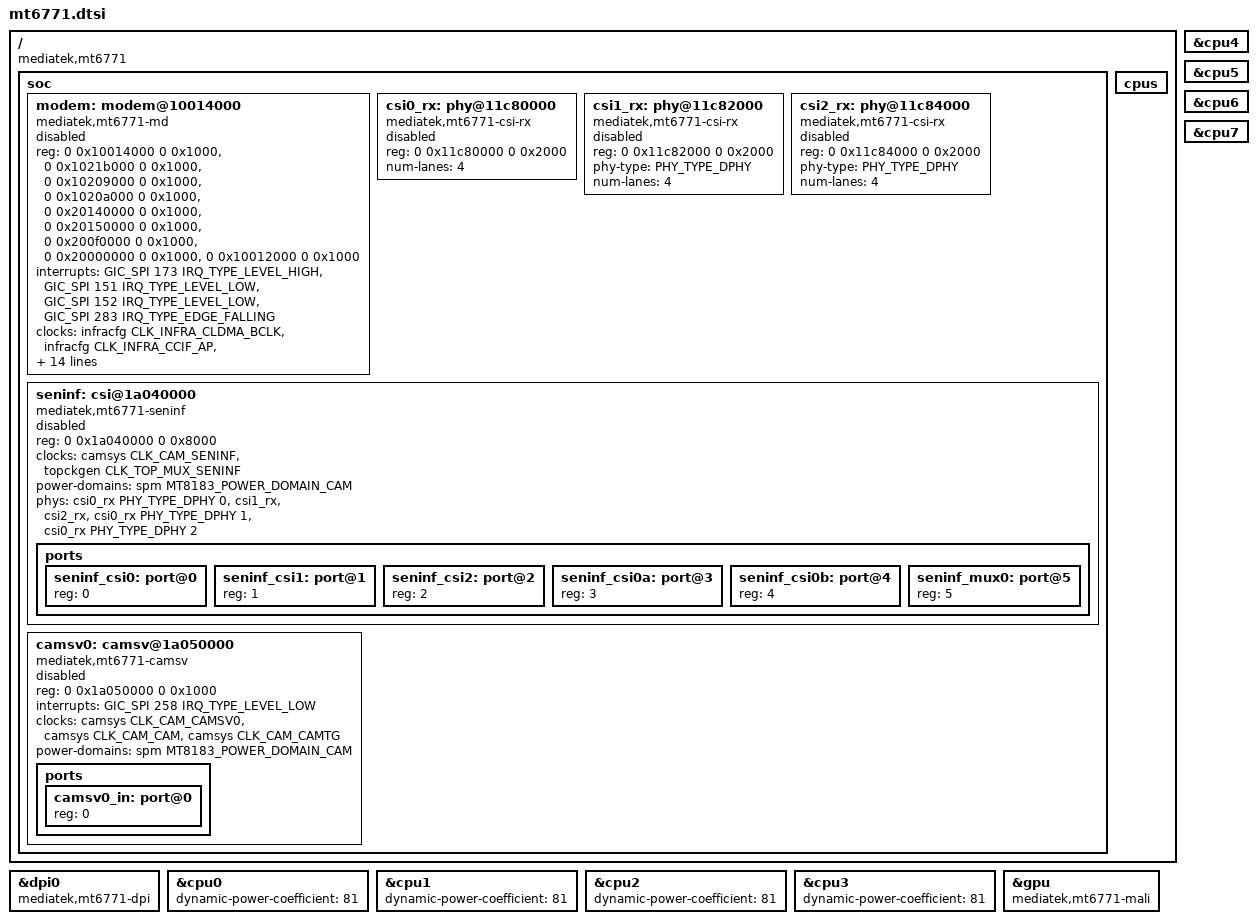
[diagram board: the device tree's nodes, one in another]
// SPDX-License-Identifier: (GPL-2.0 OR MIT)
/*
 * MediaTek MT6771 (Helio P60/P70).
 *
 * MT6771 is MT8183 silicon with a different product name and a different mix of blocks. Measured against
 * mainline's mt8183.dtsi, 85 of its 88 peripheral nodes sit at identical base addresses on MT6771; the
 * three that do not are svs (0x1100bc00), usb (0x11201000) and t-phy (0x11f40000). Everything needed to
 * reach a console — GIC at 0x0c000000, uart0 at 0x11002000, sys_timer, toprgu, topckgen, infracfg,
 * apmixedsys — matches exactly, and the vendor tree's own UART compatible is mediatek,mt6577-uart, the
 * same one mainline has matched on since 2012.
 *
 * So inherit rather than translate. An earlier version of this file described the SoC from scratch, ~400
 * lines with every node citing a line of the vendor dts (see git history, and notes 01-dtsi). That
 * translation was correct as far as it was checked — cpus, psci, timer and GIC all matched the vendor
 * exactly — but it obtains by hand what mainline already expresses in bindings that were reviewed, and
 * it differs from the only configuration known to have booted this device (Otto Pflüger's tree, which
 * does the same include).
 *
 * What is genuinely Cosmo-specific, and was read off the running device rather than from any tree, lives
 * in mt6771-planet-cosmo.dts: the memory size, the firmware-owned reservations, the framebuffer.
 */

#include <dt-bindings/phy/phy.h>

#include "mt8183.dtsi"

/ {
	compatible = "mediatek,mt6771";
};

/* same DPI block, but the vendor clocks it at 148.5 MHz for 1080p60, past the MT8183 limit */
&dpi0 {
	compatible = "mediatek,mt6771-dpi", "mediatek,mt8183-dpi";
};

/*
 * cpuidle stays off: the vendor enters idle through MCDI in the SSPM, and whether this firmware
 * honours the plain PSCI states mt8183.dtsi describes is not established. The mt8183 OPP tables
 * stay: they equal the vendor's V5_4 speed bin and are at or above the V5_T bin at every point.
 * A53 dynamic power: the vendor upower table gives 81.5 uW/MHz/V^2 at every OPP
 * (mtk_unified_power_data_mt6771.h upower_tbl_l_FY4); the A73 value 211 already matches.
 */
&cpu0 {
	/delete-property/ cpu-idle-states;
	dynamic-power-coefficient = <81>;
};

&cpu1 {
	/delete-property/ cpu-idle-states;
	dynamic-power-coefficient = <81>;
};

&cpu2 {
	/delete-property/ cpu-idle-states;
	dynamic-power-coefficient = <81>;
};

&cpu3 {
	/delete-property/ cpu-idle-states;
	dynamic-power-coefficient = <81>;
};

&cpu4 {
	/delete-property/ cpu-idle-states;
};

&cpu5 {
	/delete-property/ cpu-idle-states;
};

&cpu6 {
	/delete-property/ cpu-idle-states;
};

&cpu7 {
	/delete-property/ cpu-idle-states;
};

/*
 * The modem (MD1, generation 6293) and the two blocks the AP talks to it through: CLDMA, a
 * descriptor DMA for the network queues, and CCIF, a mailbox with a small SRAM that carries the
 * handshake and control path. MT8183 has no modem, so none of this is in mt8183.dtsi.
 * Addresses, interrupts and clocks are the vendor's mdcldma node (V:1281-1310), identical in the
 * live tree the bootloader hands the vendor kernel. The clock gates are the same bits in
 * mainline's MT8183 infracfg driver as in the vendor's MT6771 one, and the three resets are the
 * bits the vendor's md_cldma_hw_reset() and ccci_reset_ccif_hw() write by hand (infracfg 0x140
 * bit 6, 0x150 bits 2 and 8). No power-domains yet: mainline's MT8183 SPM has no MD1 domain.
 *
 * Disabled: the driver has only been built, never run against the device.
 */
/ {
	soc {
		modem: modem@10014000 {
			compatible = "mediatek,mt6771-md";
			reg = <0 0x10014000 0 0x1000>,
			      <0 0x1021b000 0 0x1000>,
			      <0 0x10209000 0 0x1000>,
			      <0 0x1020a000 0 0x1000>,
			      <0 0x20140000 0 0x1000>,
			      <0 0x20150000 0 0x1000>,
			      <0 0x200f0000 0 0x1000>,
			      <0 0x20000000 0 0x1000>,
			      <0 0x10012000 0 0x1000>;
			reg-names = "cldma-ao", "cldma-pd", "ap-ccif", "md-ccif",
				    "md-pll", "md-clksw", "md-rgu", "md-boot", "dvfsrc";
			interrupts = <GIC_SPI 173 IRQ_TYPE_LEVEL_HIGH>,
				     <GIC_SPI 151 IRQ_TYPE_LEVEL_LOW>,
				     <GIC_SPI 152 IRQ_TYPE_LEVEL_LOW>,
				     <GIC_SPI 283 IRQ_TYPE_EDGE_FALLING>;
			interrupt-names = "cldma", "ccif0", "ccif1", "wdt";
			clocks = <&infracfg CLK_INFRA_CLDMA_BCLK>,
				 <&infracfg CLK_INFRA_CCIF_AP>,
				 <&infracfg CLK_INFRA_CCIF_MD>,
				 <&infracfg CLK_INFRA_CCIF1_AP>,
				 <&infracfg CLK_INFRA_CCIF1_MD>,
				 <&infracfg CLK_INFRA_CCIF2_AP>,
				 <&infracfg CLK_INFRA_CCIF2_MD>,
				 <&infracfg CLK_INFRA_DVFSRC>;
			clock-names = "cldma", "ccif-ap", "ccif-md", "ccif1-ap",
				      "ccif1-md", "ccif2-ap", "ccif2-md", "dvfsrc";
			resets = <&infracfg MT8183_INFRACFG_AO_CLDMA_AO_SW_RST>,
				 <&infracfg MT8183_INFRACFG_AO_CLDMA_SW_RST>,
				 <&infracfg MT8183_INFRACFG_AO_AP_MD_CCIF_SW_RST>;
			reset-names = "cldma-ao", "cldma-pd", "ccif";
			mediatek,scpsys = <&scpsys>;
			mediatek,infracfg = <&infracfg>;
			mediatek,topckgen = <&topckgen>;
			mediatek,apmixedsys = <&apmixedsys>;
			status = "disabled";
		};
	};
};

/*
 * MIPI CSI-2 receiver: three analog D-PHY receivers (CSI0 can also be split into two 2 lane halves)
 * and the SENINF decoders behind them. Layout, clocks and the CAM power domain are those of
 * MT8183 (vendor mt6771.dts: analog 0x11c80000 in six 0x1000 blocks, SENINF 0x1a040000 in eight
 * pages, same camsys gate). The vendor left the SENINF interrupt (SPI 251) disabled and it is not
 * described here. Which port a sensor uses is board specific: the board hangs its sensors on the
 * ports. Disabled: the driver has only been built, never run against the device.
 *
 * CAMSV0 (0x1a050000, SPI 258) takes the stream of SENINF mux 0. The DMA has no known IOMMU port
 * yet, so the board gives it a memory region and the larbs to keep powered.
 */
/ {
	soc {
		csi0_rx: phy@11c80000 {
			compatible = "mediatek,mt6771-csi-rx", "mediatek,mt8183-csi-rx";
			reg = <0 0x11c80000 0 0x2000>;
			num-lanes = <4>;
			#phy-cells = <2>;
			status = "disabled";
		};

		csi1_rx: phy@11c82000 {
			compatible = "mediatek,mt6771-csi-rx", "mediatek,mt8183-csi-rx";
			reg = <0 0x11c82000 0 0x2000>;
			phy-type = <PHY_TYPE_DPHY>;
			num-lanes = <4>;
			#phy-cells = <0>;
			status = "disabled";
		};

		csi2_rx: phy@11c84000 {
			compatible = "mediatek,mt6771-csi-rx", "mediatek,mt8183-csi-rx";
			reg = <0 0x11c84000 0 0x2000>;
			phy-type = <PHY_TYPE_DPHY>;
			num-lanes = <4>;
			#phy-cells = <0>;
			status = "disabled";
		};

		seninf: csi@1a040000 {
			compatible = "mediatek,mt6771-seninf", "mediatek,mt8183-seninf";
			reg = <0 0x1a040000 0 0x8000>;
			clocks = <&camsys CLK_CAM_SENINF>,
				 <&topckgen CLK_TOP_MUX_SENINF>;
			clock-names = "seninf", "seninf_mux";
			power-domains = <&spm MT8183_POWER_DOMAIN_CAM>;
			phys = <&csi0_rx PHY_TYPE_DPHY 0>, <&csi1_rx>, <&csi2_rx>,
			       <&csi0_rx PHY_TYPE_DPHY 1>, <&csi0_rx PHY_TYPE_DPHY 2>;
			phy-names = "csi0", "csi1", "csi2", "csi0a", "csi0b";
			status = "disabled";

			ports {
				#address-cells = <1>;
				#size-cells = <0>;

				seninf_csi0: port@0 {
					reg = <0>;
				};

				seninf_csi1: port@1 {
					reg = <1>;
				};

				seninf_csi2: port@2 {
					reg = <2>;
				};

				seninf_csi0a: port@3 {
					reg = <3>;
				};

				seninf_csi0b: port@4 {
					reg = <4>;
				};

				seninf_mux0: port@5 {
					reg = <5>;
				};
			};
		};

		camsv0: camsv@1a050000 {
			compatible = "mediatek,mt6771-camsv", "mediatek,mt8183-camsv";
			reg = <0 0x1a050000 0 0x1000>;
			interrupts = <GIC_SPI 258 IRQ_TYPE_LEVEL_LOW>;
			clocks = <&camsys CLK_CAM_CAMSV0>,
				 <&camsys CLK_CAM_CAM>,
				 <&camsys CLK_CAM_CAMTG>;
			clock-names = "camsv", "cam", "camtg";
			power-domains = <&spm MT8183_POWER_DOMAIN_CAM>;
			status = "disabled";

			ports {
				#address-cells = <1>;
				#size-cells = <0>;

				camsv0_in: port@0 {
					reg = <0>;
				};
			};
		};
	};
};

/* mt8183.dtsi gives /cpus no label, so reach it by path. */
/ {
	cpus {
		/delete-node/ idle-states;
	};
};

/* own compatible: panfrost gates the clocks and rails on runtime suspend (GPU_PM_RT_PWR) */
&gpu {
	compatible = "mediatek,mt6771-mali", "arm,mali-bifrost";
};
